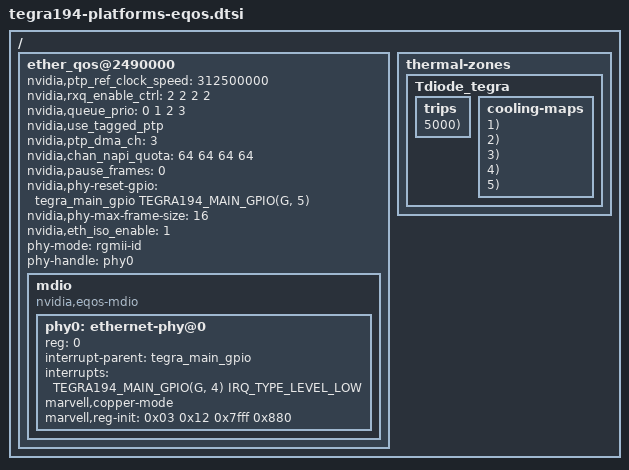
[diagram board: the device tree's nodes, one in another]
/*
 * tegra194-platforms-eqos.dtsi: Ethernet QOS DTSI file.  Common for all
 * t194 platforms boards.
 *
 * Copyright (c) 2014-2018, NVIDIA CORPORATION.  All rights reserved.
 *
 * This program is free software; you can redistribute it and/or modify
 * it under the terms of the GNU General Public License as published by
 * the Free Software Foundation; version 2 of the License.
 *
 * This program is distributed in the hope that it will be useful, but WITHOUT
 * ANY WARRANTY; without even the implied warranty of MERCHANTABILITY or
 * FITNESS FOR A PARTICULAR PURPOSE.  See the GNU General Public License for
 * more details.
 *
 * You should have received a copy of the GNU General Public License along
 * with this program; if not, write to the Free Software Foundation, Inc.,
 * 51 Franklin Street, Fifth Floor, Boston, MA  02110-1301, USA.
 *
 */
#include <dt-bindings/gpio/tegra194-gpio.h>

/ {
        ether_qos@2490000 {
		/* PTP_ref clock speed in MHz */
		nvidia,ptp_ref_clock_speed = <312500000>;
		/* rxq_enable_ctrl = <rx0 rx1 rx2 rx3>
		 * 0x0 = Not enabled, 0x1 = Enabled for AV
		 * 0x2 = Enabled for Legacy, 0x3 = Reserved
		 */
		nvidia,rxq_enable_ctrl = <2 2 2 2>;
		nvidia,queue_prio = <0 1 2 3>;

		nvidia,use_tagged_ptp;
		nvidia,ptp_dma_ch = <3>;

		nvidia,chan_napi_quota = <64 64 64 64>;
		nvidia,pause_frames = <0>; /*0=enable, 1=disable */
		nvidia,phy-reset-gpio = <&tegra_main_gpio TEGRA194_MAIN_GPIO(G, 5) 0>;
		nvidia,phy-max-frame-size = <16>;	/* size in kbytes */
		nvidia,eth_iso_enable = <1>; /*0=enable, 1=disable */
		phy-mode = "rgmii-id";
		phy-handle = <&phy0>;

		mdio {
			compatible = "nvidia,eqos-mdio";
			#address-cells = <1>;
			#size-cells = <0>;

			phy0: ethernet-phy@0 {
				reg = <0>;
				interrupt-parent = <&tegra_main_gpio>;
				interrupts = <TEGRA194_MAIN_GPIO(G, 4) IRQ_TYPE_LEVEL_LOW>;
				marvell,copper-mode;
				/* Setup LED[2] as interrupt pin (active low) */
				marvell,reg-init = <0x03 0x12 0x7fff 0x880>;
			};
		};
	};

	thermal-zones {
		Tdiode_tegra {
			trips {
				MAKE_EQOS_TRIP(m40, -40000, 5000);
				MAKE_EQOS_TRIP(m5, -5000, 5000);
				MAKE_EQOS_TRIP(p30, 30000, 5000);
				MAKE_EQOS_TRIP(p65, 65000, 5000);
				MAKE_EQOS_TRIP(p100, 100000, 5000);
			};

			cooling-maps {
				MAP_EQOS(m40, 1);
				MAP_EQOS(m5, 2);
				MAP_EQOS(p30, 3);
				MAP_EQOS(p65, 4);
				MAP_EQOS(p100, 5);
			};
		};
	};
};
